# STM32WBA50xx register map
File version: 1.0
Registers are 32-bit, read-write, reset 0x0 unless marked. A register's access mark holds for its fields unless they carry their own. Offsets are from the block's base; [hi:lo] are bit positions; {n}, {i} and the like mark numbered series.

## TAMP — Tamper and backup registers
Base 0x46007C00
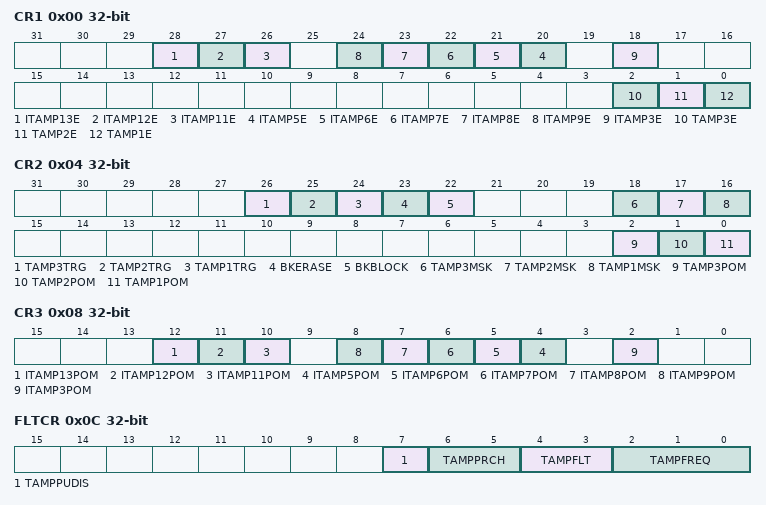
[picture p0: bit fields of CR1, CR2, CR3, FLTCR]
0x00 CR1 — TAMP configuration register 1
  [28] ITAMP13E, [27] ITAMP12E, [26] ITAMP11E, [n+15] ITAMP{n}E (n=5..9), [18] ITAMP3E, [2] TAMP3E, [1] TAMP2E, [0] TAMP1E
0x04 CR2 — TAMP configuration register 2
  [26] TAMP3TRG, [25] TAMP2TRG, [24] TAMP1TRG, [23] BKERASE, [22] BKBLOCK, [18] TAMP3MSK, [17] TAMP2MSK, [16] TAMP1MSK, [2] TAMP3POM, [1] TAMP2POM, [0] TAMP1POM
0x08 CR3 — TAMP configuration register 3
  [12] ITAMP13POM, [11] ITAMP12POM, [10] ITAMP11POM, [n-1] ITAMP{n}POM (n=5..9), [2] ITAMP3POM
0x0C FLTCR — TAMP filter control register
  [7] TAMPPUDIS
  [6:5] TAMPPRCH
    0=DURATION_1RTCCLK (Tamper pins are pre-charged before sampling during 1 RTCCLK cycle); 1=DURATION_2RTCCLK (Tamper pins are pre-charged before sampling during 2 RTCCLK cycles); 2=DURATION_4RTCCLK (Tamper pins are pre-charged before sampling during 4 RTCCLK cycles); 3=DURATION_8RTCCLK (Tamper pins are pre-charged before sampling during 8 RTCCLK cycles)
  [4:3] TAMPFLT
    0=DISABLE (Tamper filter is disabled); 1=FILTER_2SAMPLE (Tamper is activated after 2 consecutive samples at the active level); 2=FILTER_4SAMPLE (Tamper is activated after 4 consecutive samples at the active level); 3=FILTER_8SAMPLE (Tamper is activated after 8 consecutive samples at the active level)
  [2:0] TAMPFREQ
    0=SAMPLFREQDIV_32768 (Each of the tamper inputs are sampled with a frequency = RTCCLK / 32768); 1=SAMPLFREQDIV_16384 (Each of the tamper inputs are sampled with a frequency = RTCCLK / 16384); 2=SAMPLFREQDIV_8192 (Each of the tamper inputs are sampled with a frequency = RTCCLK / 8192); 3=SAMPLFREQDIV_4096 (Each of the tamper inputs are sampled with a frequency = RTCCLK / 4096); 4=SAMPLFREQDIV_2048 (Each of the tamper inputs are sampled with a frequency = RTCCLK / 2048); 5=SAMPLFREQDIV_1024 (Each of the tamper inputs are sampled with a frequency = RTCCLK / 1024); 6=SAMPLFREQDIV_512 (Each of the tamper inputs are sampled with a frequency = RTCCLK / 512); 7=SAMPLFREQDIV_256 (Each of the tamper inputs are sampled with a frequency = RTCCLK / 256)
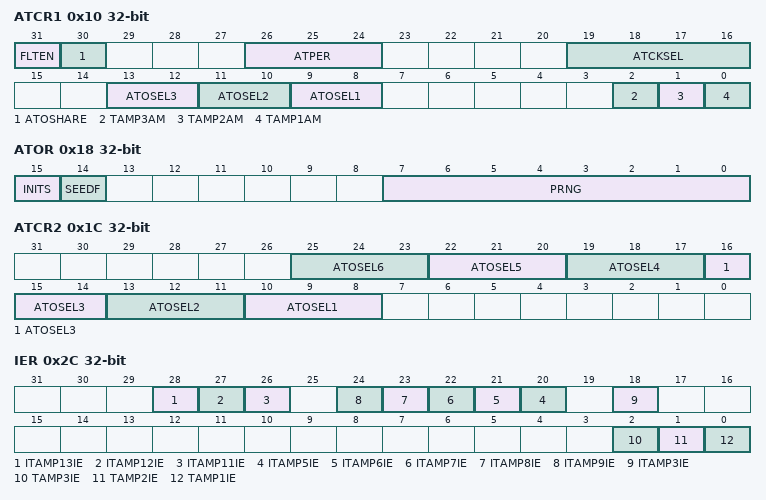
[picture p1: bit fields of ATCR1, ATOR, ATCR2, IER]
0x10 ATCR1 — TAMP filter control register 1
  [31] FLTEN, [30] ATOSHARE, [26:24] ATPER, [19:16] ATCKSEL, [13:12] ATOSEL3, [11:10] ATOSEL2, [9:8] ATOSEL1, [2] TAMP3AM, [1] TAMP2AM, [0] TAMP1AM
0x14 ATSEEDR — TAMP active tamper seed register
  [31:0] SEED
0x18 ATOR — TAMP active tamper output register
  [15] INITS, [14] SEEDF, [7:0] PRNG
0x1C ATCR2 — TAMP filter control register 2
  [3n+7:3n+5] ATOSEL{n} (n=1..6)
0x2C IER — TAMP interrupt enable register
  [28] ITAMP13IE, [27] ITAMP12IE, [26] ITAMP11IE, [n+15] ITAMP{n}IE (n=5..9), [18] ITAMP3IE, [2] TAMP3IE, [1] TAMP2IE, [0] TAMP1IE
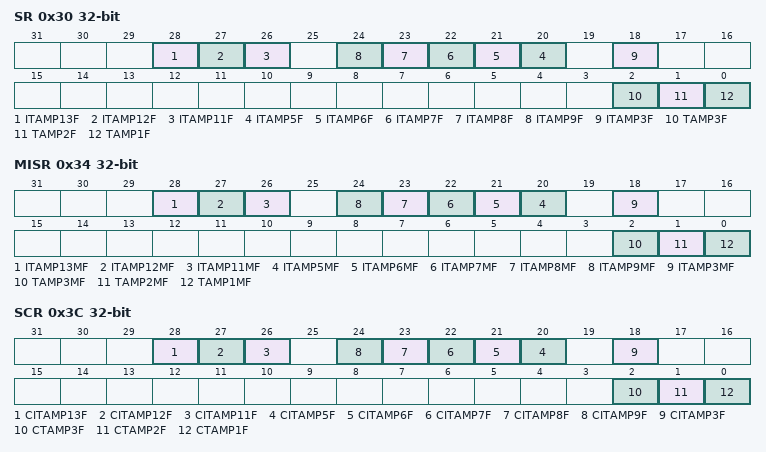
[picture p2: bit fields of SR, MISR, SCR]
0x30 SR — TAMP status register
  [28] ITAMP13F, [27] ITAMP12F, [26] ITAMP11F, [n+15] ITAMP{n}F (n=5..9), [18] ITAMP3F, [2] TAMP3F, [1] TAMP2F, [0] TAMP1F
0x34 MISR — TAMP masked interrupt status register
  [28] ITAMP13MF, [27] ITAMP12MF, [26] ITAMP11MF, [n+15] ITAMP{n}MF (n=5..9), [18] ITAMP3MF, [2] TAMP3MF, [1] TAMP2MF, [0] TAMP1MF
0x3C SCR — TAMP status clear register
  [28] CITAMP13F, [27] CITAMP12F, [26] CITAMP11F, [n+15] CITAMP{n}F (n=5..9), [18] CITAMP3F, [2] CTAMP3F, [1] CTAMP2F, [0] CTAMP1F
0x40 COUNT1R — TAMP monotonic counter 1 register
  [31:0] COUNT
{0x100+4i} BKP{i}R (i=0..31) — TAMP backup register {i}

## EXTI — Asynch Interrupt/Event Controller (EXTI)
Base 0x46022000
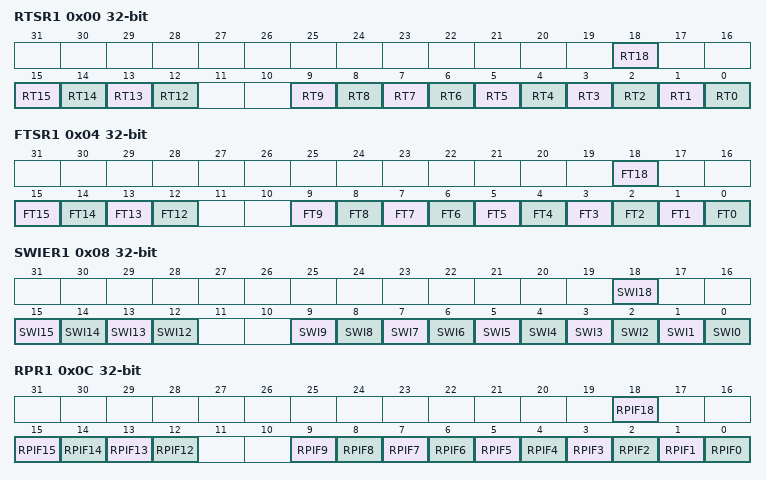
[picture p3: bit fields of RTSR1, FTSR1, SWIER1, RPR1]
0x00 RTSR1 — EXTI Rising Trigger Selection Register 1
  [18] RT18 — Rising trigger configuration for input line 18
  [n] RT{n} (n=12..15) — Rising trigger configuration for input line {n}
  [n] RT{n} (n=0..9) — Rising trigger configuration for input line {n}
0x04 FTSR1 — EXTI Falling Trigger Selection Register 1
  [18] FT18 — Falling trigger configuration for input line 18
  [n] FT{n} (n=12..15) — Falling trigger configuration for input line {n}
  [n] FT{n} (n=0..9) — Falling trigger configuration for input line {n}
0x08 SWIER1 — EXTI Software Interrupt event Register 1
  [18] SWI18 — Software Interrupt on line 18
  [n] SWI{n} (n=12..15) — Software Interrupt on line {n}
  [n] SWI{n} (n=0..9) — Software Interrupt on line {n}
0x0C RPR1 — EXTI Rising Pending Register 1
  [18] RPIF18 — Rising Pending Interrupt Flag on line 18
  [n] RPIF{n} (n=12..15) — Rising Pending Interrupt Flag on line {n}
  [n] RPIF{n} (n=0..9) — Rising Pending Interrupt Flag on line {n}
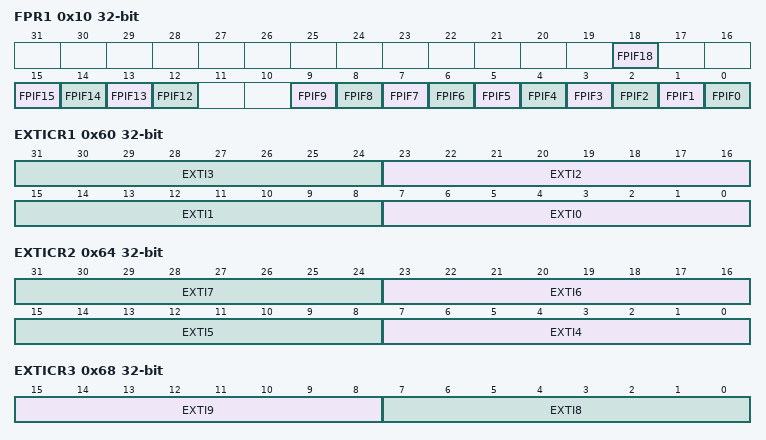
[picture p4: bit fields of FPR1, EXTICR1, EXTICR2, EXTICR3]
0x10 FPR1 — EXTI Falling Pending Register 1
  [18] FPIF18 — Falling Pending Interrupt Flag on line 18
  [n] FPIF{n} (n=12..15) — Falling Pending Interrupt Flag on line {n}
  [n] FPIF{n} (n=0..9) — Falling Pending Interrupt Flag on line {n}
0x60 EXTICR1 — EXIT External Interrupt Configuration Register, 0x60 -- 0x6C
  [8n+7:8n] EXTI{n} (n=0..3) — EXTI {n} configuration
0x64 EXTICR2 — EXIT External Interrupt Configuration Register, 0x60 -- 0x6C
  [8n-25:8n-32] EXTI{n} (n=4..7) — EXTI {n} configuration
0x68 EXTICR3 — EXIT External Interrupt Configuration Register, 0x60 -- 0x6C
  [15:8] EXTI9 — EXTI 9 configuration
  [7:0] EXTI8 — EXTI 8 configuration
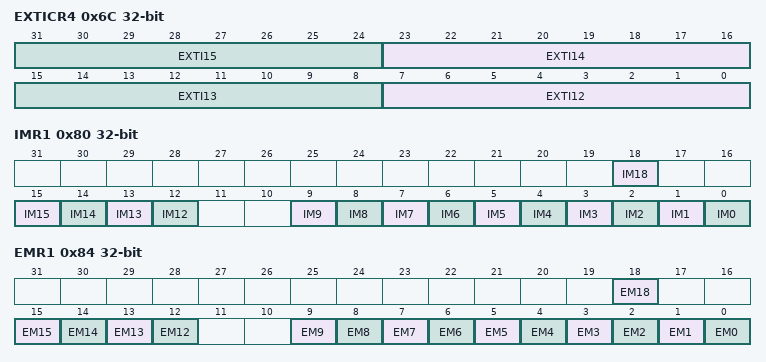
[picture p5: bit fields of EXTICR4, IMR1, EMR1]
0x6C EXTICR4 — EXIT External Interrupt Configuration Register, 0x60 -- 0x6C
  [8n-89:8n-96] EXTI{n} (n=12..15) — EXTI {n} configuration
0x80 IMR1 — EXTI Interrupt Mask Register 1
  [18] IM18 — Interrupt Mask on line 18
  [n] IM{n} (n=12..15) — Interrupt Mask on line {n}
  [n] IM{n} (n=0..9) — Interrupt Mask on line {n}
0x84 EMR1 — EXTI Event Mask Register 1
  [18] EM18 — Event Mask on line 18
  [n] EM{n} (n=12..15) — Event Mask on line {n}
  [n] EM{n} (n=0..9) — Event Mask on line {n}

## DBGMCU — Debug MCU
Base 0xE0044000
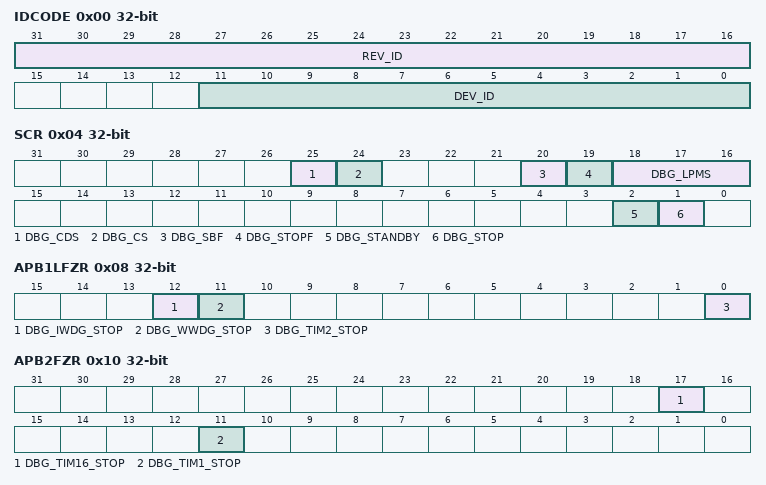
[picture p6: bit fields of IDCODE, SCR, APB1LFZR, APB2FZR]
0x00 IDCODE — MCU device ID code
  [31:16] REV_ID, [11:0] DEV_ID
0x04 SCR — Debug MCU status and configuration register
  [25] DBG_CDS, [24] DBG_CS, [20] DBG_SBF, [19] DBG_STOPF, [18:16] DBG_LPMS, [2] DBG_STANDBY, [1] DBG_STOP
0x08 APB1LFZR — Debug MCU APB1 freeze register 1
  [12] DBG_IWDG_STOP, [11] DBG_WWDG_STOP, [0] DBG_TIM2_STOP
0x0C APB1HFZR — Debug MCU APB1 freeze register 2
0x10 APB2FZR — Debug MCU APB2 freeze register
  [17] DBG_TIM16_STOP, [11] DBG_TIM1_STOP
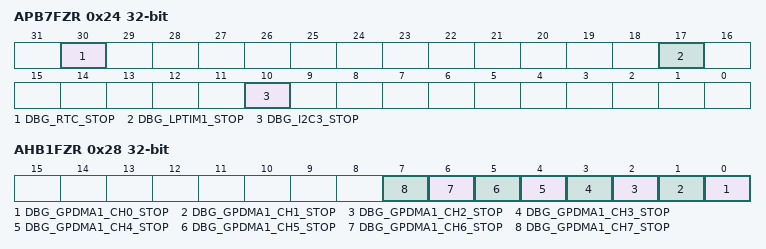
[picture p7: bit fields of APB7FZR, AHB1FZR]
0x24 APB7FZR — Debug MCU APB7 freeze register
  [30] DBG_RTC_STOP, [17] DBG_LPTIM1_STOP, [10] DBG_I2C3_STOP
0x28 AHB1FZR — Debug MCU AHB1 freeze register
  [n] DBG_GPDMA1_CH{n}_STOP (n=0..7)
